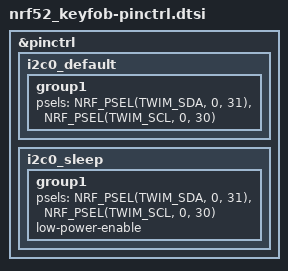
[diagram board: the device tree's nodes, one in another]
/*
 * Copyright (c) 2022 Maximilian Deubel
 * SPDX-License-Identifier: Apache-2.0
 */

&pinctrl {
	i2c0_default: i2c0_default {
		group1 {
			psels = <NRF_PSEL(TWIM_SDA, 0, 31)>,
				<NRF_PSEL(TWIM_SCL, 0, 30)>;
		};
	};

	i2c0_sleep: i2c0_sleep {
		group1 {
			psels = <NRF_PSEL(TWIM_SDA, 0, 31)>,
				<NRF_PSEL(TWIM_SCL, 0, 30)>;
			low-power-enable;
		};
	};
};
